# GIOCD register map
Vendor: Texas Instruments
Peripheral module from a debugger description file (folder ucd3138128A).
Registers are 32-bit, access not given, no defined reset value unless marked. A register's access mark holds for its fields unless they carry their own. Offsets are as the file gives them; lines under a group give offsets from that group; [hi:lo] are bit positions; {n}, {i} and the like mark numbered series; 'fields as' and 'values as' point back to an identical list; <NAME> marks a mode.

## GIOCD
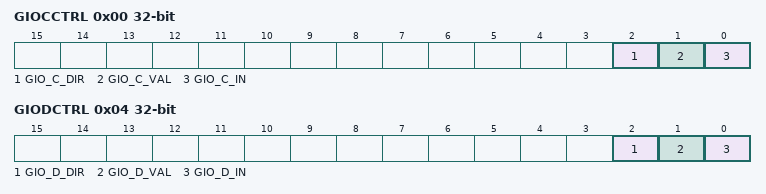
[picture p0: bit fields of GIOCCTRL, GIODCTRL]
0x00 GIOCCTRL
  [2] GIO_C_DIR rw — Pin Direction in GPIO Mode (1 = Input/0 = Output) 0 = default
  [1] GIO_C_VAL rw — TX Data Pin Output in GPIO Mode
  [0] GIO_C_IN rw — TX Data Pin Value
0x04 GIODCTRL
  [2] GIO_D_DIR rw — Pin Direction in GPIO Mode (1 = Input/0 = Output) 0 = default
  [1] GIO_D_VAL rw — TX Data Pin Output in GPIO Mode
  [0] GIO_D_IN rw — TX Data Pin Value
